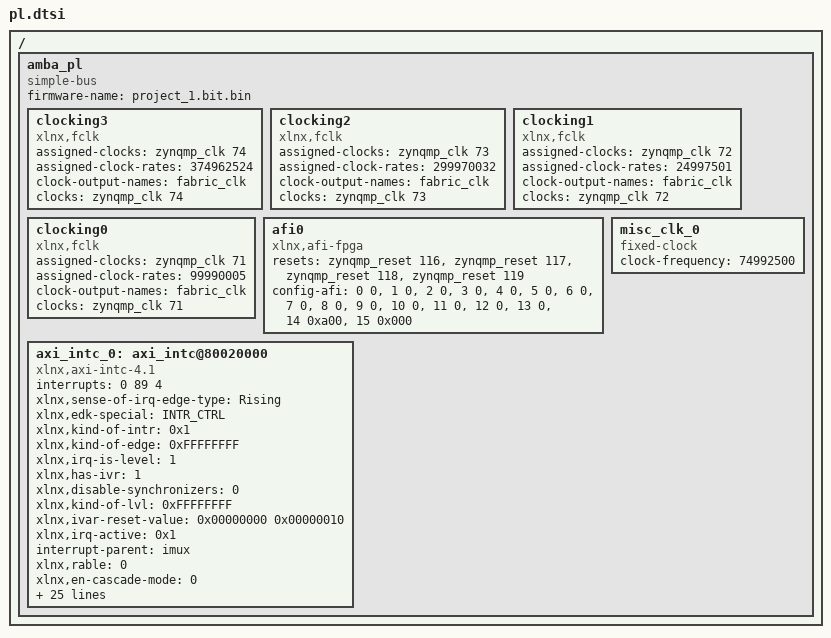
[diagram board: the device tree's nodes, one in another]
/ {
	amba_pl: amba_pl {
		ranges;
		compatible = "simple-bus";
		#address-cells = <2>;
		#size-cells = <2>;
		firmware-name = "project_1.bit.bin";
		clocking3: clocking3 {
			compatible = "xlnx,fclk";
			assigned-clocks = <&zynqmp_clk 74>;
			assigned-clock-rates = <374962524>;
			#clock-cells = <0>;
			clock-output-names = "fabric_clk";
			clocks = <&zynqmp_clk 74>;
		};
		clocking2: clocking2 {
			compatible = "xlnx,fclk";
			assigned-clocks = <&zynqmp_clk 73>;
			assigned-clock-rates = <299970032>;
			#clock-cells = <0>;
			clock-output-names = "fabric_clk";
			clocks = <&zynqmp_clk 73>;
		};
		clocking1: clocking1 {
			compatible = "xlnx,fclk";
			assigned-clocks = <&zynqmp_clk 72>;
			assigned-clock-rates = <24997501>;
			#clock-cells = <0>;
			clock-output-names = "fabric_clk";
			clocks = <&zynqmp_clk 72>;
		};
		clocking0: clocking0 {
			compatible = "xlnx,fclk";
			assigned-clocks = <&zynqmp_clk 71>;
			assigned-clock-rates = <99990005>;
			#clock-cells = <0>;
			clock-output-names = "fabric_clk";
			clocks = <&zynqmp_clk 71>;
		};
		afi0: afi0 {
			status = "okay";
			compatible = "xlnx,afi-fpga";
			resets = <&zynqmp_reset 116>, <&zynqmp_reset 117>, <&zynqmp_reset 118>, <&zynqmp_reset 119>;
			config-afi = < 0 0>, <1 0>, <2 0>, <3 0>, <4 0>, <5 0>, <6 0>, <7 0>, <8 0>, <9 0>, <10 0>, <11 0>, <12 0>, <13 0>, <14 0xa00>, <15 0x000>;
		};
		misc_clk_0: misc_clk_0 {
			compatible = "fixed-clock";
			clock-frequency = <74992500>;
			#clock-cells = <0>;
		};
		axi_intc_0: axi_intc@80020000 {
			#interrupt-cells = <2>;
			interrupts = < 0 89 4 >;
			xlnx,sense-of-irq-edge-type = "Rising";
			xlnx,edk-special = "INTR_CTRL";
			xlnx,kind-of-intr = <0x1>;
			xlnx,kind-of-edge = <0xFFFFFFFF>;
			xlnx,irq-is-level = <1>;
			xlnx,has-ivr = <1>;
			compatible = "xlnx,axi-intc-4.1" , "xlnx,xps-intc-1.00.a";
			xlnx,disable-synchronizers = <0>;
			xlnx,kind-of-lvl = <0xFFFFFFFF>;
			xlnx,ivar-reset-value = <0x00000000 0x00000010>;
			xlnx,irq-active = <0x1>;
			interrupt-parent = <&imux>;
			xlnx,rable = <0>;
			xlnx,en-cascade-mode = <0>;
			xlnx,ip-name = "axi_intc";
			xlnx,has-ilr = <0>;
			reg = <0x0 0x80020000 0x0 0x1000>;
			xlnx,addr-width = <0x20>;
			clocks = <&misc_clk_0>;
			xlnx,s-axi-aclk-freq-mhz = <0x4784b74>;
			xlnx,num-sw-intr = <0>;
			xlnx,irq-connection = <1>;
			xlnx,num-intr-inputs = <0x1>;
			xlnx,has-sie = <1>;
			xlnx,enable-async = <0>;
			xlnx,has-cie = <1>;
			xlnx,num-sync-ff = <2>;
			xlnx,edk-iptype = "PERIPHERAL";
			xlnx,mb-clk-not-connected = <1>;
			xlnx,has-ipr = <1>;
			xlnx,sense-of-irq-level-type = "Active_High";
			xlnx,cascade-master = <0>;
			xlnx,processor-clk-freq-mhz = <100>;
			status = "okay";
			xlnx,is-fast = <0x0>;
			clock-names = "s_axi_aclk";
			xlnx,has-fast = <0>;
			xlnx,ivar-rst-val = <0x10>;
			interrupt-controller;
			interrupt-names = "irq";
			xlnx,async-intr = <0xFFFFFFFF>;
			xlnx,name = "axi_intc_0";
		};
	};
};
